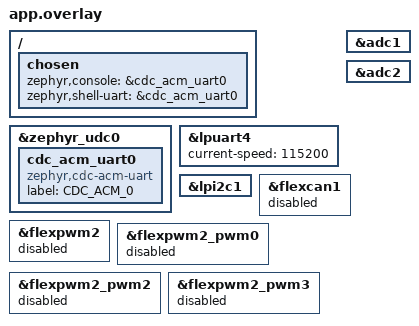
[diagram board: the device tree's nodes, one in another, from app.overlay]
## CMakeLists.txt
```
add_subdirectory(lib/)
```

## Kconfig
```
rsource "lib/Kconfig"
```

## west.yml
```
manifest:
  projects:
    - name: zephyr
      url: https://github.com/zephyrproject-rtos/zephyr
      revision: main
      path: zephyr
      clone-depth: 1
      west-commands: scripts/west-commands.yml

  self:
    path: modules/lua
    west-commands: scripts/west-commands.yml
```

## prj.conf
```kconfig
# Language features
CONFIG_PRINTK=y
CONFIG_ASSERT=y
CONFIG_NEWLIB_LIBC=y
CONFIG_NEWLIB_LIBC_FLOAT_PRINTF=y
CONFIG_NEWLIB_LIBC_FLOAT_SCANF=y
CONFIG_LOG=y
CONFIG_INIT_STACKS=y
CONFIG_FPU=y=y
CONFIG_CBPRINTF_FP_SUPPORT=y

CONFIG_CMSIS_DSP=y
CONFIG_CMSIS_DSP_BASICMATH=y
CONFIG_CMSIS_DSP_COMPLEXMATH=y
CONFIG_CMSIS_DSP_CONTROLLER=y
CONFIG_CMSIS_DSP_FASTMATH=y
CONFIG_CMSIS_DSP_FILTERING=y
CONFIG_CMSIS_DSP_INTERPOLATION=y
CONFIG_CMSIS_DSP_MATRIX=y
CONFIG_CMSIS_DSP_QUATERNIONMATH=y
CONFIG_CMSIS_DSP_STATISTICS=y
CONFIG_CMSIS_DSP_SUPPORT=y
CONFIG_CMSIS_DSP_TRANSFORM=y
CONFIG_CMSIS_DSP_SVM=y
CONFIG_CMSIS_DSP_BAYES=y
CONFIG_CMSIS_DSP_DISTANCE=y
CONFIG_CMSIS_DSP_TABLES=y
CONFIG_CMSIS_DSP_TABLES_ALL_FAST=y
CONFIG_CMSIS_DSP_TABLES_ALL_FFT=y
CONFIG_CMSIS_DSP_MATRIXCHECK=y
# CONFIG_THREAD_NAME=y
# CONFIG_THREAD_MONITOR=y
# CONFIG_THREAD_STACK_INFO=y
# CONFIG_THREAD_RUNTIME_STATS=y
# CONFIG_THREAD_RUNTIME_STATS_USE_TIMING_FUNCTIONS=y
CONFIG_MAIN_STACK_SIZE=4096
## Random
CONFIG_ENTROPY_GENERATOR=y
# CONFIG_TEST_RANDOM_GENERATOR=y
CONFIG_CTR_DRBG_CSPRNG_GENERATOR=y

## File
CONFIG_DISK_ACCESS=y
#CONFIG_DISK_DRIVERS=y
CONFIG_FILE_SYSTEM=y
CONFIG_FILE_SYSTEM_SHELL=y
#CONFIG_FILE_SYSTEM_LITTLEFS=y
CONFIG_FAT_FILESYSTEM_ELM=y
CONFIG_FS_FATFS_EXFAT=y
CONFIG_FS_FATFS_LFN=y # support long filenames
CONFIG_FS_FATFS_MOUNT_MKFS=y
# CONFIG_SDMMC_USDHC=y
CONFIG_DISK_DRIVER_SDMMC=y
CONFIG_SDMMC_LOG_LEVEL_DBG=y

## Peripherals
CONFIG_GPIO=y
CONFIG_GPIO_SHELL=y
# CONFIG_PINMUX=y
CONFIG_I2C=y
CONFIG_I2C_SHELL=y
# CONFIG_EEPROM=n
CONFIG_FLASH=y
# CONFIG_FLASH_PAGE_LAYOUT=y
# CONFIG_FLASH_SHELL=y
# CONFIG_FLASH_MAP=y
# CONFIG_FLASH_MAP_SHELL=y
CONFIG_HWINFO=y
CONFIG_HWINFO_SHELL=y
# CONFIG_CAN=y
# CONFIG_CAN_SHELL=y
CONFIG_ADC=y
CONFIG_ADC_ASYNC=y
CONFIG_ADC_SHELL=y
# CONFIG_DAC=y
# CONFIG_DAC_SHELL=y
CONFIG_PWM=y
CONFIG_PWM_SHELL=y
CONFIG_SPI=y
# CONFIG_LED=y
# CONFIG_LED_PWM=y
CONFIG_NETWORKING=y
CONFIG_NET_IPV6=n
CONFIG_NET_IPV4=y
CONFIG_NET_DHCPV4=y
CONFIG_NET_MGMT=y
CONFIG_NET_MGMT_EVENT=y
CONFIG_NET_SHELL=y
## Shell
CONFIG_SHELL=y
CONFIG_KERNEL_SHELL=y
CONFIG_DEVICE_SHELL=y
CONFIG_SHELL_STACK_SIZE=8192
CONFIG_SHELL_BACKEND_SERIAL=y
CONFIG_SHELL_BACKEND_SERIAL_CHECK_DTR=y
CONFIG_POSIX_CLOCK=y
# CONFIG_STATS_SHELL=y
CONFIG_DATE_SHELL=y
# CONFIG_SETTINGS_SHELL=y
## Console
# CONFIG_CONSOLE_SUBSYS=y
# CONFIG_CONSOLE_GETCHAR=y
# CONFIG_CONSOLE_GETCHAR_BUFSIZE=4096
# CONFIG_CONSOLE_PUTCHAR_BUFSIZE=4096
## Serial
CONFIG_SERIAL=y
CONFIG_UART_USE_RUNTIME_CONFIGURE=y
CONFIG_UART_LINE_CTRL=y
# CONFIG_USB_UART_CONSOLE=y
CONFIG_USB_DEVICE_STACK=y
CONFIG_USB_DEVICE_PRODUCT="USB Terminal"
CONFIG_SHELL_BACKEND_SERIAL_INIT_PRIORITY=51

## Memory
CONFIG_HEAP_MEM_POOL_SIZE=262144

## Modules
CONFIG_ZSL=y
CONFIG_ZSL_SINGLE_PRECISION=y
# CONFIG_ZSL_PLATFORM_OPT=2
CONFIG_ZSL_VECTOR_INLINE=y
CONFIG_ZSL_MATRIX_INLINE=y
CONFIG_ZSL_SHELL=y
CONFIG_ZSL_SHELL_CLR=y
CONFIG_ZSL_SHELL_ORIENT=y
```

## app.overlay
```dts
/ {
	chosen {
		zephyr,console = &cdc_acm_uart0;
        zephyr,shell-uart = &cdc_acm_uart0;
	};
};

&zephyr_udc0 {
	cdc_acm_uart0: cdc_acm_uart0 {
		compatible = "zephyr,cdc-acm-uart";
		label = "CDC_ACM_0";
	};
};

&lpuart4 {
         status="okay";
         current-speed = <115200>;
};

&lpi2c1 {
  status="okay";
};

&adc1 {
      status = "okay";
};

&adc2 {
      status = "okay";
};

&flexcan1 {
	status = "disabled";
};

&flexpwm2 {
    status = "disabled";
};

&flexpwm2_pwm0 {
    status = "disabled";
};

&flexpwm2_pwm2 {
    status = "disabled";
};

&flexpwm2_pwm3 {
    status = "disabled";
};
```

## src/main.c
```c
#include <zephyr.h>
#include <device.h>
#include <sys/printk.h>
#include <usb/usb_device.h>
#include <storage/disk_access.h>
#include <fs/fs.h>
#include <ff.h>
#include <string.h>
#include <stdio.h>
#include <stdlib.h>

#include <fsl_pwm.h>
#include "lua/lauxlib.h"
#include "lua/lua.h"
#include "lua/lualib.h"

lua_State * L;


static FATFS fat_fs;
/* mounting info */
static struct fs_mount_t mp = {
    .type = FS_FATFS,
    .fs_data = &fat_fs,
    .mnt_point = "/SD:",
};

void main(void)
{
    if (usb_enable(NULL)) {
        return;
    }

    // Manually setup the PWM
    pwm_config_t pwmConfig;
    PWM_GetDefaultConfig(&pwmConfig);

    pwmConfig.reloadLogic = kPWM_ReloadPwmFullCycle;
    pwmConfig.clockSource = kPWM_BusClock;
    pwmConfig.enableDebugMode = true;

    if (PWM_Init((void*)0x403E0000, 0, &pwmConfig) == kStatus_Fail) {
        printk("[PWM] PWM Init Fail\n");
    } else {
        *(uint16_t*)0x403E002C = 0;
        *(uint16_t*)0x403E008C = 0;
        *(uint16_t*)0x403E00EC = 0;
        *(uint16_t*)0x403E014C = 0;

        pwm_signal_param_t pwmSignal;
        pwmSignal.pwmChannel = kPWM_PwmA;
        pwmSignal.level = kPWM_HighTrue;
        pwmSignal.dutyCyclePercent = 75;
        PWM_SetupPwm((void*)0x403E0000, kPWM_Module_0, &pwmSignal, 1, kPWM_EdgeAligned, 2500000, 250000000);

        PWM_SetPwmLdok((void*)0x403E0000, kPWM_Control_Module_0, true);
        PWM_StartTimer((void*)0x403E0000, kPWM_Control_Module_0);
    }

    if (disk_access_init("USDHC_1") != 0) {
        printk("[SD] Storage init ERROR!");

        int res = fs_mount(&mp);
        if (res == FR_OK) {
            printk("[SD] Mounted\n");
        } else {
            printk("[SD] Error mounting disk.\n");
        }
    }

    /* k_sleep(K_MSEC(5000)); */

    L = luaL_newstate();
    luaL_openlibs(L);
    fflush(stdout);

    printk("[INIT DONE]\n");
}
```

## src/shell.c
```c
#include <zephyr.h>
#include <device.h>
#include <shell/shell.h>
#include <fs/fs.h>
#include <ff.h>

#include "lua/lauxlib.h"
#include "lua/lua.h"

extern lua_State* L;

void cmd_lua_loadfile(const struct shell * shell, size_t argc, char ** argv) {
    if (argc == 2) {
        char* path = argv[1];

        // Load init.lua
        struct fs_file_t init;
        fs_file_t_init(&init);
        if(0 == fs_open(&init, path, 1)) {
            fs_seek(&init, 0, FS_SEEK_END);
            size_t size = fs_tell(&init);
            char * str = malloc(size+1);
            str[size] = 0;
            fs_seek(&init, 0, FS_SEEK_SET);
            fs_read(&init, str, size);
            int err = luaL_dostring(L, str);
            if (err) {shell_print(shell, "Lua file executed with errors: %i", err);} else {
                shell_print(shell, "Lua file executed successfully.");
            }
            free(str);
        } else {
            shell_print(shell, "Could not open the file %s", path);
        }
        fs_close(&init);
    } else {
        shell_print(shell, "Invalid # of arguments %i", argc);
    }
}

void cmd_lua(const struct shell * shell, size_t argc, char ** argv) {
    if (argc == 2) {
        char* arg = argv[1];
        luaL_loadstring(L, arg);
        int err = lua_pcall(L, 0, 0, 0);
        if (err) {
            const char* str = luaL_checkstring(L, 1);
            if (str) {
                shell_print(shell, "<ERR %i: %s>", err, str);
                lua_pop(L, 1);
            } else {
                shell_print(shell, "<ERR %i>", err);
            }
        }
        fflush(stdout);
    } else if (argc == 1) {
        shell_print(shell, "Lua 5.4.4 %i", L);
    } else {
        shell_print(shell, "Invalid # of arguments %i", argc);
    }
}

SHELL_CMD_REGISTER(lua, NULL, "Execute lua code", cmd_lua);
SHELL_CMD_REGISTER(lua_lf, NULL, "Run the given lua file", cmd_lua_loadfile);
```
